# MC1322x register map
Registers are 32-bit, access not given, no defined reset value unless marked. A register's access mark holds for its fields unless they carry their own. Addresses are absolute; registers are grouped by the start of their names; [hi:lo] are bit positions; {n}, {i} and the like mark numbered series; 'fields as' and 'values as' point back to an identical list.

## FUNC
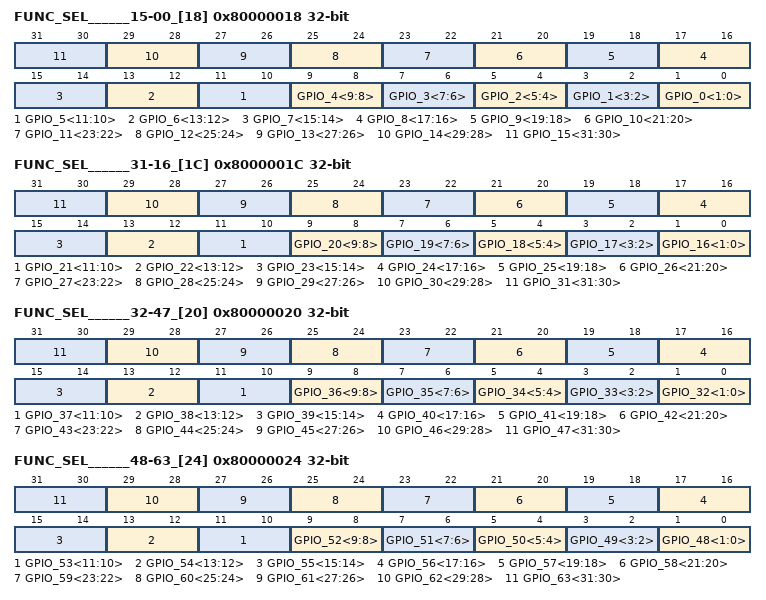
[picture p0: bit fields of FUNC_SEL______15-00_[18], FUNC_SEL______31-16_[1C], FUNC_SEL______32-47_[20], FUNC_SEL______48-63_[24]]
0x80000018 FUNC_SEL______15-00_[18]
  [2n+1:2n] GPIO_{n}<{2n+1}:{2n}> (n=0..15)
0x8000001C FUNC_SEL______31-16_[1C]
  [2n-31:2n-32] GPIO_{n}<{2n-31}:{2n-32}> (n=16..31)
0x80000020 FUNC_SEL______32-47_[20]
  [2n-63:2n-64] GPIO_{n}<{2n-63}:{2n-64}> (n=32..47)
0x80000024 FUNC_SEL______48-63_[24]
  [2n-95:2n-96] GPIO_{n}<{2n-95}:{2n-96}> (n=48..63)

## IP
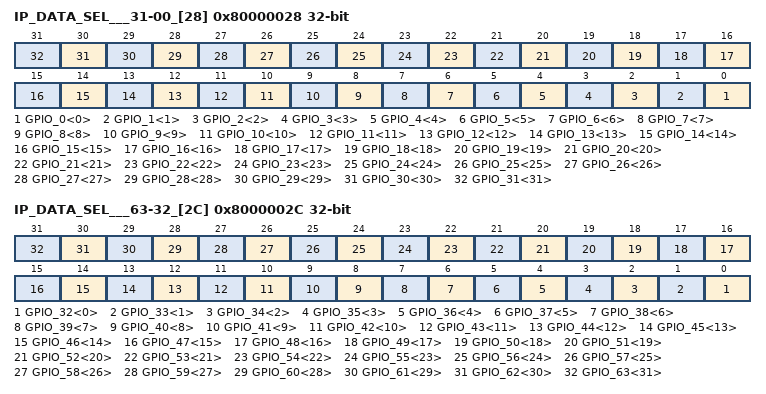
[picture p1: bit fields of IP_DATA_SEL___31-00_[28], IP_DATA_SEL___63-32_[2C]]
0x80000028 IP_DATA_SEL___31-00_[28]
  [n] GPIO_{n}<{n}> (n=0..31)
0x8000002C IP_DATA_SEL___63-32_[2C]
  [n-32] GPIO_{n}<{n-32}> (n=32..63)

## PULLUP
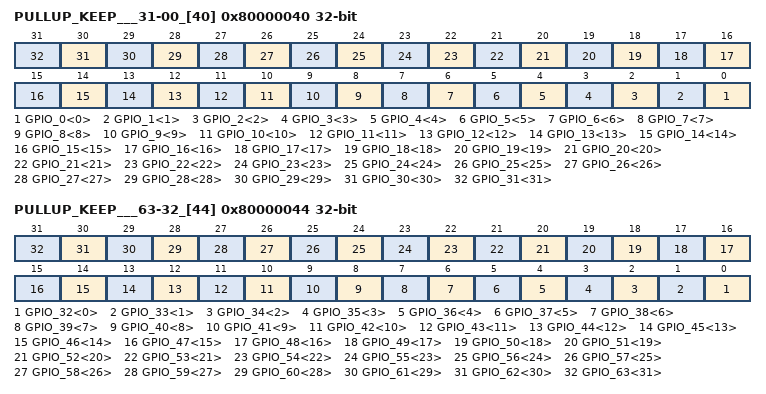
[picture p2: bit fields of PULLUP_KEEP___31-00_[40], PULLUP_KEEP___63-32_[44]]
0x80000040 PULLUP_KEEP___31-00_[40]
  [n] GPIO_{n}<{n}> (n=0..31)
0x80000044 PULLUP_KEEP___63-32_[44]
  [n-32] GPIO_{n}<{n-32}> (n=32..63)

## DATA
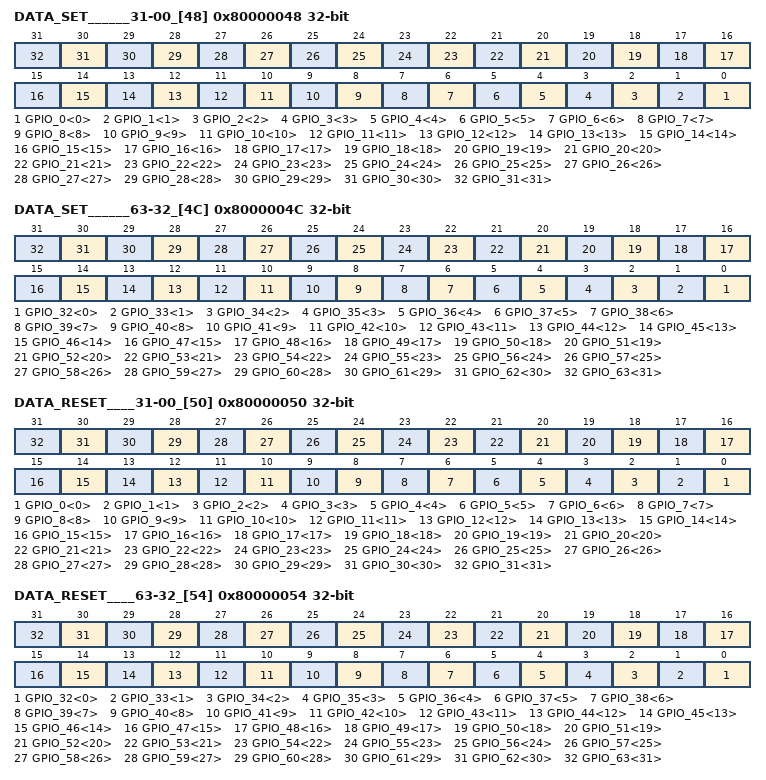
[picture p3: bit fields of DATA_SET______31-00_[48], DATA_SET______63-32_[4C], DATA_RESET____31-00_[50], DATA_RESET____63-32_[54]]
0x80000048 DATA_SET______31-00_[48]
  [n] GPIO_{n}<{n}> (n=0..31)
0x8000004C DATA_SET______63-32_[4C]
  [n-32] GPIO_{n}<{n-32}> (n=32..63)
0x80000050 DATA_RESET____31-00_[50]
  [n] GPIO_{n}<{n}> (n=0..31)
0x80000054 DATA_RESET____63-32_[54]
  [n-32] GPIO_{n}<{n-32}> (n=32..63)
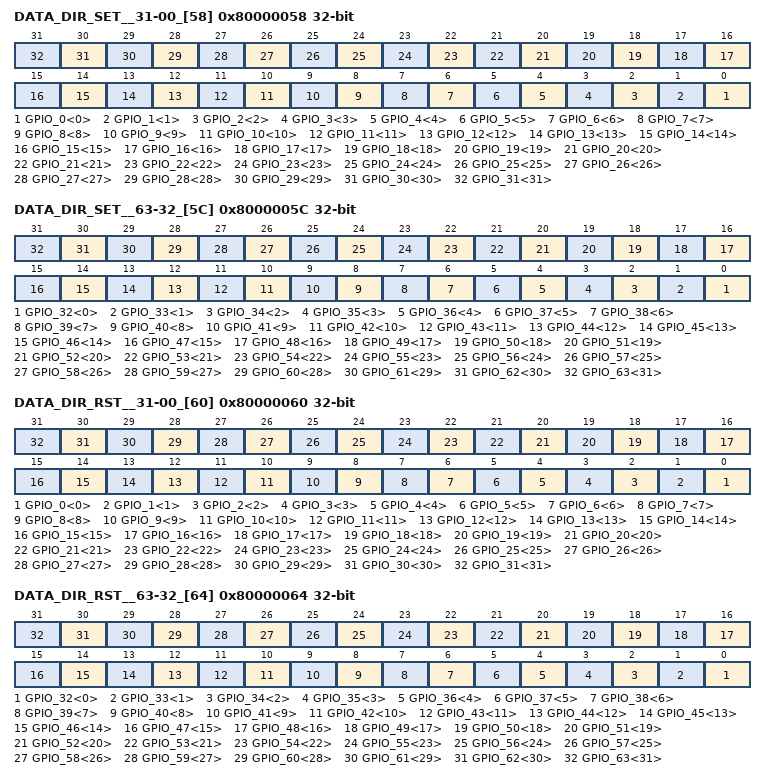
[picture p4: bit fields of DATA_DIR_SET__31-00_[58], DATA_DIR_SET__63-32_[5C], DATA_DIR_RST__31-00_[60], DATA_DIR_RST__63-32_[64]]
0x80000058 DATA_DIR_SET__31-00_[58]
  [n] GPIO_{n}<{n}> (n=0..31)
0x8000005C DATA_DIR_SET__63-32_[5C]
  [n-32] GPIO_{n}<{n-32}> (n=32..63)
0x80000060 DATA_DIR_RST__31-00_[60]
  [n] GPIO_{n}<{n}> (n=0..31)
0x80000064 DATA_DIR_RST__63-32_[64]
  [n-32] GPIO_{n}<{n-32}> (n=32..63)

## SPI
0x80002000 SPI_TX_DATA_[00]
0x80002004 SPI_RX_DATA_[04]
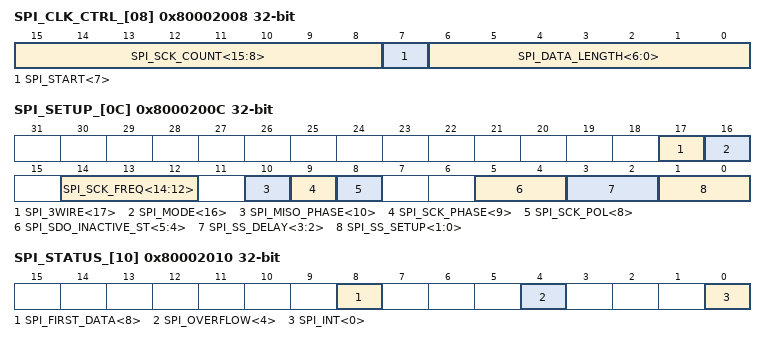
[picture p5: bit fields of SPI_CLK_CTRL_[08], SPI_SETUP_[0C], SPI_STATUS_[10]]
0x80002008 SPI_CLK_CTRL_[08]
  [15:8] SPI_SCK_COUNT<15:8>, [7] SPI_START<7>, [6:0] SPI_DATA_LENGTH<6:0>
0x8000200C SPI_SETUP_[0C]
  [17] SPI_3WIRE<17>, [16] SPI_MODE<16>, [14:12] SPI_SCK_FREQ<14:12>, [10] SPI_MISO_PHASE<10>, [9] SPI_SCK_PHASE<9>, [8] SPI_SCK_POL<8>, [5:4] SPI_SDO_INACTIVE_ST<5:4>, [3:2] SPI_SS_DELAY<3:2>, [1:0] SPI_SS_SETUP<1:0>
0x80002010 SPI_STATUS_[10]
  [8] SPI_FIRST_DATA<8>, [4] SPI_OVERFLOW<4>, [0] SPI_INT<0>

## WU
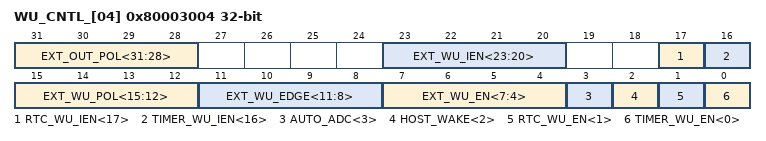
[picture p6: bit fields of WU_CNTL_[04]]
0x80003004 WU_CNTL_[04]
  [31:28] EXT_OUT_POL<31:28>, [23:20] EXT_WU_IEN<23:20>, [17] RTC_WU_IEN<17>, [16] TIMER_WU_IEN<16>, [15:12] EXT_WU_POL<15:12>, [11:8] EXT_WU_EDGE<11:8>, [7:4] EXT_WU_EN<7:4>, [3] AUTO_ADC<3>, [2] HOST_WAKE<2>, [1] RTC_WU_EN<1>, [0] TIMER_WU_EN<0>
0x80003020 WU_COUNT_[20]
0x80003024 WU_TIMEOUT_[24]

## COP
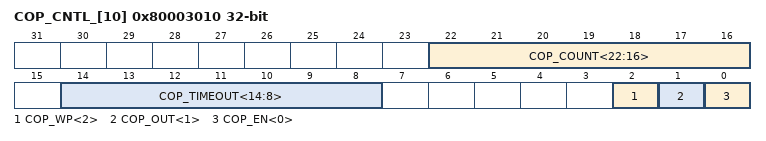
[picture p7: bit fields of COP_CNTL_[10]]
0x80003010 COP_CNTL_[10]
  [22:16] COP_COUNT<22:16>, [14:8] COP_TIMEOUT<14:8>, [2] COP_WP<2>, [1] COP_OUT<1>, [0] COP_EN<0>
0x80003014 COP_SERVICE_[14]

## RTC
0x80003028 RTC_COUNT_[28]
0x8000302C RTC_TIMEOUT_[2C]

## CAL
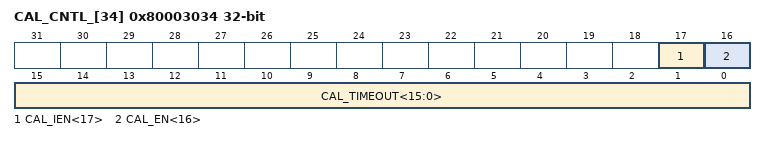
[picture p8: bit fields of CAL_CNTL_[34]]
0x80003034 CAL_CNTL_[34]
  [17] CAL_IEN<17>, [16] CAL_EN<16>, [15:0] CAL_TIMEOUT<15:0>
0x80003038 CAL_COUNT_[38]

## VREG
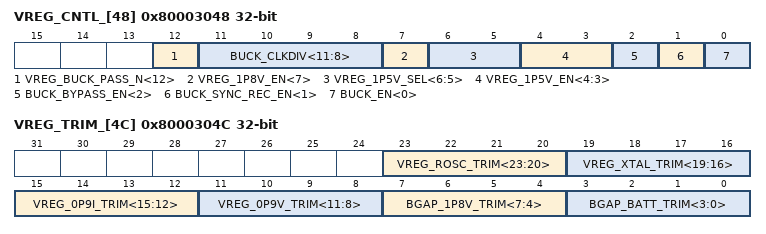
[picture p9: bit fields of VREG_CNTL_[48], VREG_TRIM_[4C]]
0x80003048 VREG_CNTL_[48]
  [12] VREG_BUCK_PASS_N<12>, [11:8] BUCK_CLKDIV<11:8>, [7] VREG_1P8V_EN<7>, [6:5] VREG_1P5V_SEL<6:5>, [4:3] VREG_1P5V_EN<4:3>, [2] BUCK_BYPASS_EN<2>, [1] BUCK_SYNC_REC_EN<1>, [0] BUCK_EN<0>
0x8000304C VREG_TRIM_[4C]
  [23:20] VREG_ROSC_TRIM<23:20>, [19:16] VREG_XTAL_TRIM<19:16>, [15:12] VREG_0P9I_TRIM<15:12>, [11:8] VREG_0P9V_TRIM<11:8>, [7:4] BGAP_1P8V_TRIM<7:4>, [3:0] BGAP_BATT_TRIM<3:0>

## MACA
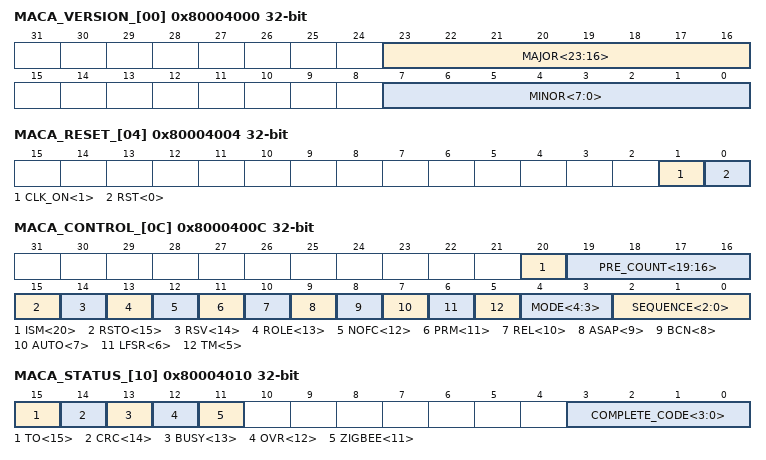
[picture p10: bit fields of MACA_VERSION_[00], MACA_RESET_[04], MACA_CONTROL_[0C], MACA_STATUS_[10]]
0x80004000 MACA_VERSION_[00]
  [23:16] MAJOR<23:16>, [7:0] MINOR<7:0>
0x80004004 MACA_RESET_[04]
  [1] CLK_ON<1>, [0] RST<0>
0x80004008 MACA_RANDOM_[08]
0x8000400C MACA_CONTROL_[0C]
  [20] ISM<20>, [19:16] PRE_COUNT<19:16>, [15] RSTO<15>, [14] RSV<14>, [13] ROLE<13>, [12] NOFC<12>, [11] PRM<11>, [10] REL<10>, [9] ASAP<9>, [8] BCN<8>, [7] AUTO<7>, [6] LFSR<6>, [5] TM<5>, [4:3] MODE<4:3>, [2:0] SEQUENCE<2:0>
0x80004010 MACA_STATUS_[10]
  [15] TO<15>, [14] CRC<14>, [13] BUSY<13>, [12] OVR<12>, [11] ZIGBEE<11>, [3:0] COMPLETE_CODE<3:0>
0x80004014 MACA_FRAME_PENDING_[14]_<0>
0x80004018 MACA_FREQ_CHANNEL_[18]_<3:0>
0x8000401C MACA_ED_VALUE_[1C]
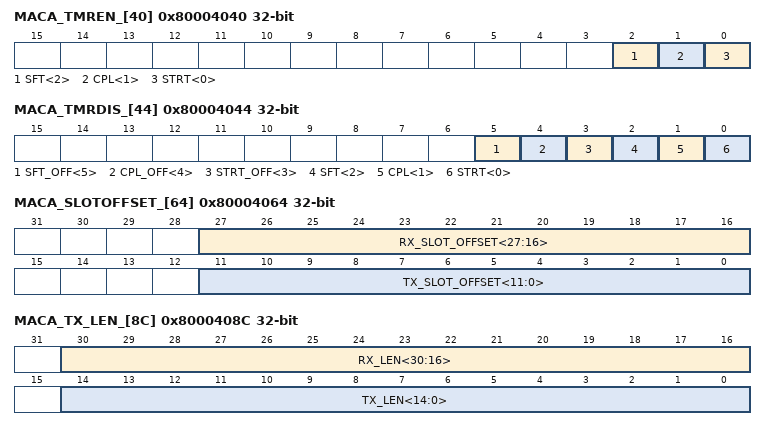
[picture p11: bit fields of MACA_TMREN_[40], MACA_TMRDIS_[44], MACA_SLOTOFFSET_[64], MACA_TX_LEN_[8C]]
0x80004040 MACA_TMREN_[40]
  [2] SFT<2>, [1] CPL<1>, [0] STRT<0>
0x80004044 MACA_TMRDIS_[44]
  [5] SFT_OFF<5>, [4] CPL_OFF<4>, [3] STRT_OFF<3>, [2] SFT<2>, [1] CPL<1>, [0] STRT<0>
0x80004048 MACA_CLK_[48]
0x8000404C MACA_STARTCLK_[4C]
0x80004050 MACA_CPLCLK_[50]
0x80004054 MACA_SFTCLK_[54]
0x80004058 MACA_CLKOFFSET_[58]
0x8000405C MACA_RELCLK_[5C]
0x80004060 MACA_CPLTIM_[60]
0x80004064 MACA_SLOTOFFSET_[64]
  [27:16] RX_SLOT_OFFSET<27:16>, [11:0] TX_SLOT_OFFSET<11:0>
0x80004068 MACA_TIMESTAMP_[68]
0x80004080 MACA_DMA_RX_[80]
0x80004084 MACA_DMA_TX_[84]
0x80004088 MACA_DMA_POLL_[88]
0x8000408C MACA_TX_LEN_[8C]
  [30:16] RX_LEN<30:16>, [14:0] TX_LEN<14:0>
0x80004090 MACA_TX_SEQNR_[90]_<7:0>
0x80004094 MACA_SET_RX_FIFO_LVL_[94]_<15:0>
0x80004098 MACA_GET_RX_LVL_RECVBYTES_[98]_<15:0>
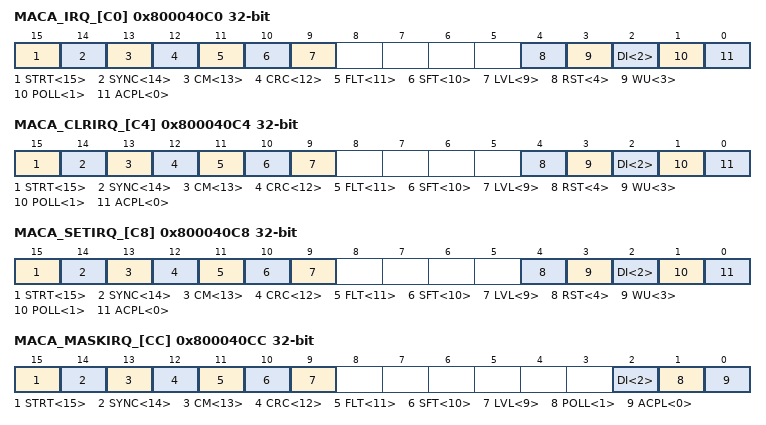
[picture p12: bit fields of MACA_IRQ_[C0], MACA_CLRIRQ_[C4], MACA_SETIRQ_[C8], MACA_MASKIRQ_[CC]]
0x800040C0 MACA_IRQ_[C0]
  [15] STRT<15>, [14] SYNC<14>, [13] CM<13>, [12] CRC<12>, [11] FLT<11>, [10] SFT<10>, [9] LVL<9>, [4] RST<4>, [3] WU<3>, [2] DI<2>, [1] POLL<1>, [0] ACPL<0>
0x800040C4 MACA_CLRIRQ_[C4]
  fields as MACA_IRQ_[C0]
0x800040C8 MACA_SETIRQ_[C8]
  fields as MACA_IRQ_[C0]
0x800040CC MACA_MASKIRQ_[CC]
  [15] STRT<15>, [14] SYNC<14>, [13] CM<13>, [12] CRC<12>, [11] FLT<11>, [10] SFT<10>, [9] LVL<9>, [2] DI<2>, [1] POLL<1>, [0] ACPL<0>
0x80004100 MACA_MACPANID_[100]_<15:0>
0x80004104 MACA_MAC16ADDR_[104]_<15:0>
0x80004108 MACA_MAC64HI_[108]
0x8000410C MACA_MAC64LO_[10C]
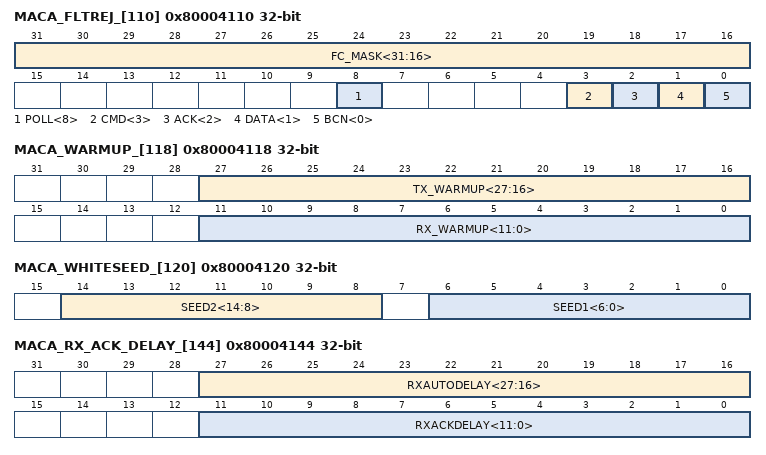
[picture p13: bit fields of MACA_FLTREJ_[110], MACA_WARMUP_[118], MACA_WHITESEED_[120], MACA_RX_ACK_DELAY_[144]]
0x80004110 MACA_FLTREJ_[110]
  [31:16] FC_MASK<31:16>, [8] POLL<8>, [3] CMD<3>, [2] ACK<2>, [1] DATA<1>, [0] BCN<0>
0x80004114 MACA_CLK_DIV_[114]_<15:0>
0x80004118 MACA_WARMUP_[118]
  [27:16] TX_WARMUP<27:16>, [11:0] RX_WARMUP<11:0>
0x8000411C MACA_PREAMBLE_[11C]
0x80004120 MACA_WHITESEED_[120]
  [14:8] SEED2<14:8>, [6:0] SEED1<6:0>
0x80004124 MACA_FRAMESYNC0_[124]
0x80004128 MACA_FRAMESYNC1_[128]
0x80004140 MACA_TX_ACK_DELAY_[140]
  [11:0] TXACKDELAY<11:0>
0x80004140 MACA_TXA_CK_DELAY_[140]
  [27:16] TXPOLLDELAY<27:16>
0x80004144 MACA_RX_ACK_DELAY_[144]
  [27:16] RXAUTODELAY<27:16>, [11:0] RXACKDELAY<11:0>
0x80004148 MACA_EOF_DELAY_[148]_<11:0>
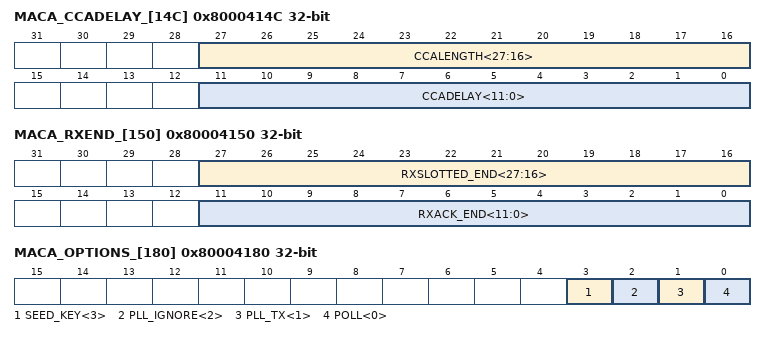
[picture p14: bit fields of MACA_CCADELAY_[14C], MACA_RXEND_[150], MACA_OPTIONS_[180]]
0x8000414C MACA_CCADELAY_[14C]
  [27:16] CCALENGTH<27:16>, [11:0] CCADELAY<11:0>
0x80004150 MACA_RXEND_[150]
  [27:16] RXSLOTTED_END<27:16>, [11:0] RXACK_END<11:0>
0x80004154 MACA_TX_CCA_DELAY_[154]_<11:0>
0x80004158 MACA_KEY3_[158]
0x8000415C MACA_KEY2_[15C]
0x80004160 MACA_KEY1_[160]
0x80004164 MACA_KEY0_[164]
0x80004180 MACA_OPTIONS_[180]
  [3] SEED_KEY<3>, [2] PLL_IGNORE<2>, [1] PLL_TX<1>, [0] POLL<0>
